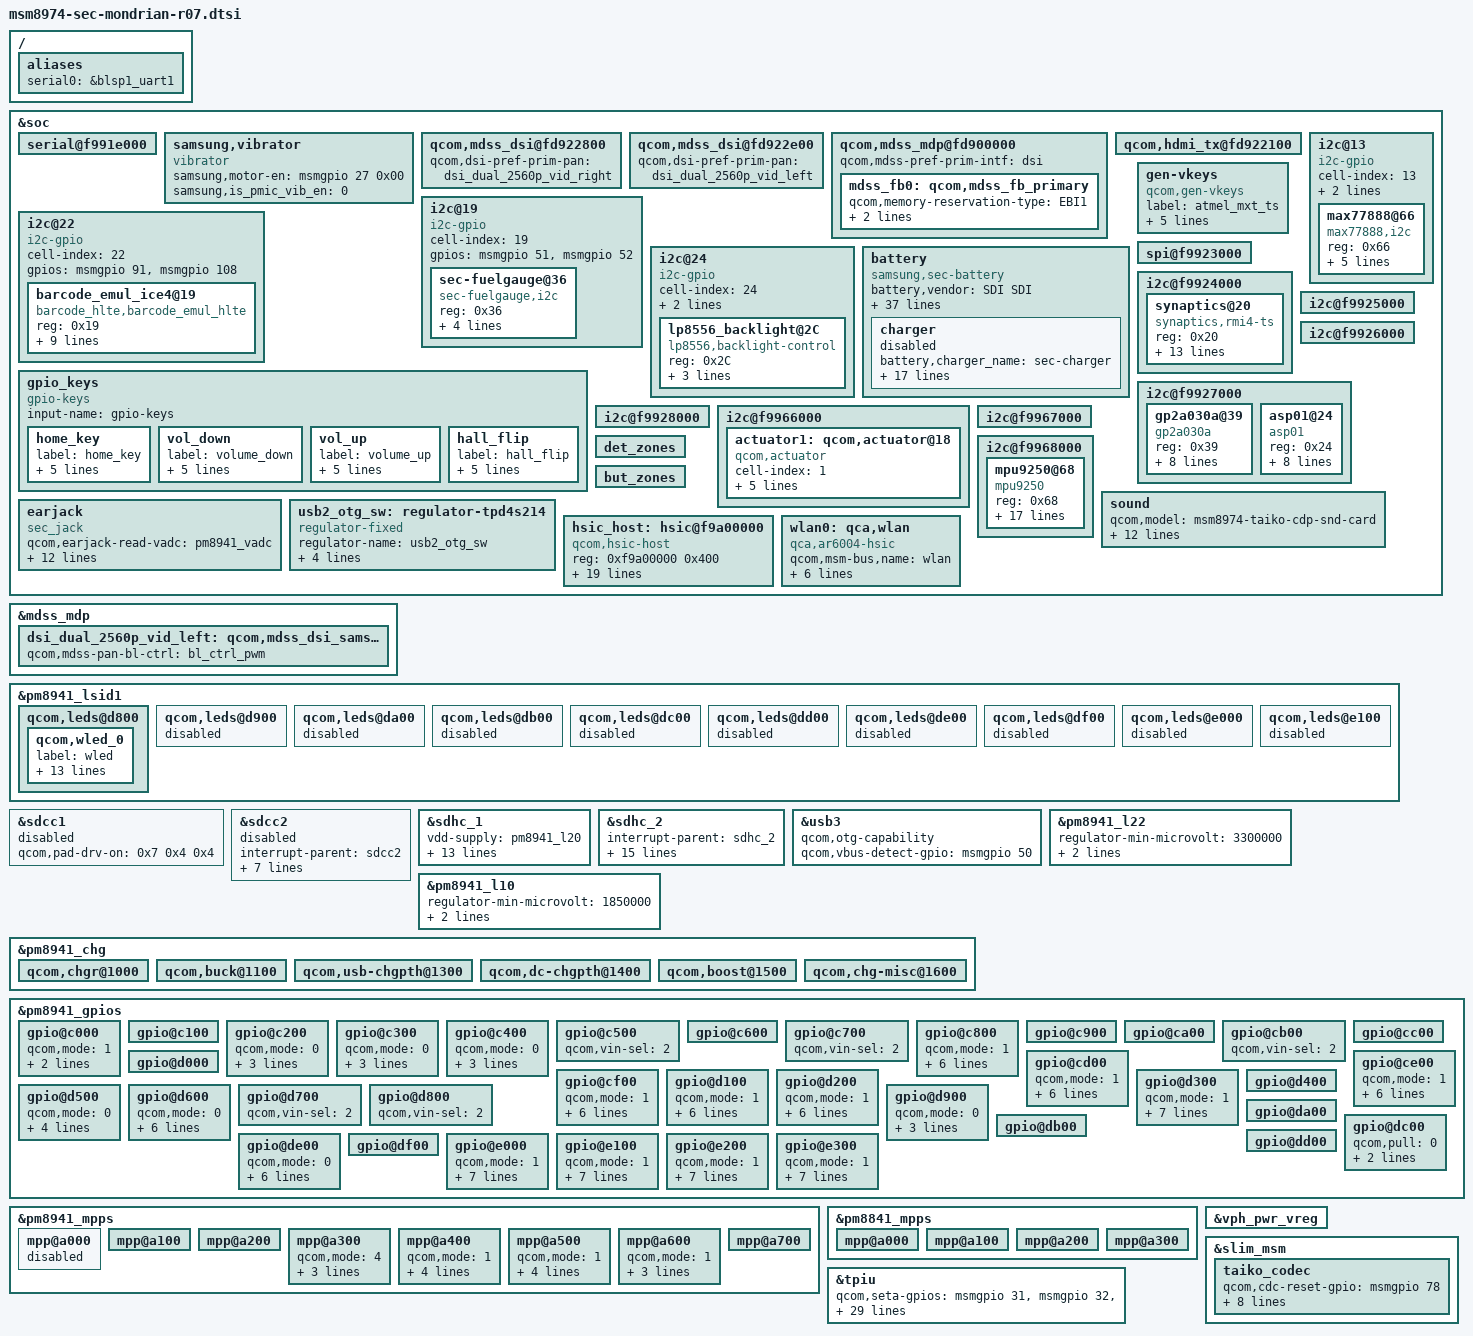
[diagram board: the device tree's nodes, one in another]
/* Copyright (c) 2012-2013, The Linux Foundation. All rights reserved.
 *
 * This program is free software; you can redistribute it and/or modify
 * it under the terms of the GNU General Public License version 2 and
 * only version 2 as published by the Free Software Foundation.
 *
 * This program is distributed in the hope that it will be useful,
 * but WITHOUT ANY WARRANTY; without even the implied warranty of
 * MERCHANTABILITY or FITNESS FOR A PARTICULAR PURPOSE.  See the
 * GNU General Public License for more details.
 */

/include/ "msm8974-leds.dtsi"
/include/ "msm8974-camera-sensor-skate.dtsi"
/include/ "msm8974-sii8240_mhl-mondrian-r00.dtsi"

/ {
	aliases {
		serial0 = &blsp1_uart1;
	};
};

&soc {
	serial@f991e000 {
		status = "ok";
	};

	samsung,vibrator{
                compatible = "vibrator";
                samsung,motor-en = <&msmgpio 27 0x00>;
		samsung,is_pmic_vib_en = <0>;
		status = "ok";
	};


	qcom,mdss_dsi@fd922800 {
		qcom,dsi-pref-prim-pan = <&dsi_dual_2560p_vid_right>;
	};

	qcom,mdss_dsi@fd922e00 {
		qcom,dsi-pref-prim-pan = <&dsi_dual_2560p_vid_left>;
	};

	qcom,mdss_mdp@fd900000 {
		qcom,mdss-pref-prim-intf = "dsi";
		mdss_fb0: qcom,mdss_fb_primary {
			qcom,memory-reservation-type = "EBI1";
			qcom,memblock-reserve = <0x03200000 0x01F00000>;
			qcom,mdss-fb-split = <800 800>;
		};
	};

	qcom,hdmi_tx@fd922100 {
		status = "ok";
	};

    i2c@13 {
        cell-index = <13>;
        compatible = "i2c-gpio";
        gpios = <&msmgpio 83 0 /* sda */
                 &msmgpio 84 0 /* scl */
                >;
		i2c-gpio,delay-us = <2>;
		#address-cells = <1>;
		#size-cells = <0>;
		max77888@66 {
		    compatible = "max77888,i2c";
		    reg = <0x66>;
		    interrupt-parent = <&pm8941_gpios>;
		    interrupts = <23 0>;
		    max77888,irq-gpio = <&pm8941_gpios 23 0x00>;
		    max77888,irq-base = <357>;
		    max77888,wakeup = <1>;
		};
    };

	i2c@19 {
        cell-index = <19>;
        compatible = "i2c-gpio";
        gpios = <&msmgpio 51 0 /* sda */
                 &msmgpio 52 0 /* scl */
                >;
		sec-fuelgauge@36 {
			compatible = "sec-fuelgauge,i2c";
			reg = <0x36>;
			fuelgauge,jig_gpio = <&msmgpio 76 0>;
			fuelgauge,fuel_int = <&pm8941_gpios 26 0x1>;
			fuelgauge,capacity_calculation_type = <7>;
			fuelgauge,fuel_alert_soc = <2>;
		};
	};

	i2c@22 {
		cell-index = <22>;
		compatible = "i2c-gpio";
		gpios = <&msmgpio 91 0 /* sda */
		&msmgpio 108 0 /* scl */
		>;

		barcode_emul_ice4@19 {
			compatible = "barcode_hlte,barcode_emul_hlte";
			reg = <0x19>;
			interrupt-parent = <&msmgpio>;
			interrupts = <64 0>;
			barcode,cresetb = <&msmgpio 57 0x01>;
			barcode,reset_n = <&msmgpio 132 0x00>;
			barcode,scl-gpio = <&msmgpio 108 0x00>;
			barcode,sda-gpio = <&msmgpio 91 0x00>;
			barcode,irq-gpio = <&msmgpio 64 0x00>;
			barcode,ir_led_en = <&pm8941_gpios 35 0x00>;
			barcode,i2c-pull-up = <1>;
		};
	};

	i2c@24 {
		cell-index = <24>;
		compatible = "i2c-gpio";
		gpios = <&msmgpio 10 0 /* sda */
				&msmgpio 11 0 /* scl */
		>;

		i2c-gpio,delay-us = <4>;

		lp8556_backlight@2C {
				compatible = "lp8556,backlight-control";
				reg = <0x2C>;
				lp8556,en-gpio = <&pm8941_gpios 19 0x00>;
				lp8556,scl-gpio = <&msmgpio 11 0x00>;
				lp8556,sda-gpio = <&msmgpio 10 0x00>;
		};
	};

	battery {
		status = "okay";
		compatible = "samsung,sec-battery";
		battery,vendor = "SDI SDI";
		battery,charger_name = "sec-charger";
		battery,fuelgauge_name = "sec-fuelgauge";
		battery,technology = <2>; /* POWER_SUPPLY_TECHNOLOGY_LION */
		battery,bat_irq_attr = <0x3>;

		battery,chip_vendor = "QCOM";
		battery,temp_adc_type = <1>; /* SEC_BATTERY_ADC_TYPE_AP */

		battery,polling_time = <10 30 30 30 3600>;

		battery,adc_check_count = <6>;

		battery,cable_check_type = <5>; /* SEC_BATTERY_CABLE_CHECK_NOUSBCHARGE | SEC_BATTERY_CABLE_CHECK_PSY */
		battery,cable_source_type = <1>; /* SEC_BATTERY_CABLE_SOURCE_EXTERNAL */
		battery,event_check;
		battery,event_waiting_time = <600>;
		battery,polling_type = <1>; /* SEC_BATTERY_MONITOR_ALARM */
		battery,monitor_initial_count = <3>;

		battery,battery_check_type = <4>; /* SEC_BATTERY_CHECK_FUELGAUGE */
		battery,check_count = <0>;
		battery,check_adc_max = <1440>;
		battery,check_adc_min = <0>;

		battery,ovp_uvlo_check_type = <3>; /* SEC_BATTERY_OVP_UVLO_CHGPOLLING */

		battery,thermal_source = <0>; /* SEC_BATTERY_THERMAL_SOURCE_FG */

		battery,temp_check_type = <2>; /* _BATTERY_TEMP_CHECK_TEMP */
		battery,temp_check_count = <1>;
		battery,full_check_type = <7>; /* SEC_BATTERY_FULLCHARGED_CHGPSY */
		battery,full_check_type_2nd = <3>; /* SEC_BATTERY_FULLCHARGED_TIME */
		battery,full_check_count = <1>;
		battery,chg_gpio_full_check = <0>;
		battery,chg_polarity_full_check = <1>;

		/* SEC_BATTERY_FULL_CONDITION_SOC |
		   SEC_BATTERY_FULL_CONDITION_NOTIMEFULL |
		   SEC_BATTERY_FULL_CONDITION_VCELL */
		battery,full_condition_type = <13>;
		battery,full_condition_soc = <97>;
		battery,full_condition_vcell = <4300>;

		battery,recharge_check_count = <1>;
		battery,recharge_condition_type = <4>; /* SEC_BATTERY_RECHARGE_CONDITION_VCELL */
		battery,recharge_condition_soc = <98>;
		battery,recharge_condition_vcell = <4300>;

		battery,charging_total_time = <36000>;
		battery,recharging_total_time = <5400>;
		battery,charging_reset_time = <0>;

		charger{
			status = "disable";
			/* Charger */
			battery,charger_name = "sec-charger";
			battery,chg_gpio_en = <0>;
			battery,chg_polarity_en = <0>;
			battery,chg_gpio_status = <0>;
			battery,chg_polarity_status = <0>;
			battery,chg_float_voltage = <4350>;
			battery,ovp_uvlo_check_type = <3>; /* SEC_BATTERY_OVP_UVLO_CHGPOLLING */
			battery,full_check_type = <7>; /* SEC_BATTERY_FULLCHARGED_CHGPSY */

			battery,input_current_limit = <1900 460 460 1900 460 900 1000 460 460 1000 650 1900 1900 460 1300 300 700 1300 300 1000 1900 460 460>;
			battery,fast_charging_current = <2100 0 460 2100 460 1200 1000 460 0 1200 750 2100 2100 0 1300 300 700 1300 300 1000 2100 0 0>;
			battery,full_check_current_1st = <350 0 350 350 350 350 350 350 0 350 350 350 350 0 350 350 350 350 350 350 350 0 0>;
			battery,full_check_current_2nd = <1200 0 1200 1200 1200 1200 1200 1200 0 1200 1200 1200 1200 0 1200 1200 1200 1200 1200 1200 1200 0 0>;
			battery,full_check_current_1st_sdi = <200 0 200 200 200 200 200 200 0 200 200 200 200 0 200 200 200 200 200 200 200 0 0>;
		};
	};

	qcom,hdmi_tx@fd922100 {
		status = "ok";
	};



	gen-vkeys {
		compatible = "qcom,gen-vkeys";
		label = "atmel_mxt_ts";
		qcom,disp-maxx = <720>;
		qcom,disp-maxy = <1280>;
		qcom,panel-maxx = <760>;
		qcom,panel-maxy = <1424>;
		qcom,key-codes = <158 139 102 217>;
	};

	gpio_keys {
		compatible = "gpio-keys";
		input-name = "gpio-keys";

		home_key {
			label = "home_key";
			gpios = <&pm8941_gpios 3 0x1>;
			linux,input-type = <1>;
			linux,code = <172>;
			gpio-key,wakeup;
			debounce-interval = <15>;
		};

		vol_down {
			label = "volume_down";
			gpios = <&pm8941_gpios 2 0x1>;
			linux,input-type = <1>;
			linux,code = <114>;
			gpio-key,wakeup;
			debounce-interval = <15>;
		};

		vol_up {
			label = "volume_up";
			gpios = <&pm8941_gpios 5 0x1>;
			linux,input-type = <1>;
			linux,code = <115>;
			gpio-key,wakeup;
			debounce-interval = <15>;
		};

		hall_flip {
			label = "hall_flip";
			gpios = <&pm8941_gpios 31 0>;
			linux,input-type = <1>;
			linux,code = <0x15>;
			gpio-key,wakeup;
			debounce-interval = <15>;
		};
	};

	/* BLSP#1 */
	spi@f9923000 {
		status = "okay";
	};

	/* BLSP#2 */
	i2c@f9924000 {
		status = "okay";
		synaptics@20 {
			compatible = "synaptics,rmi4-ts";
			reg = <0x20>;
			interrupt-parent = <&pm8941_gpios>;
			interrupts = <30 0>;
			avdd-supply = <&pm8941_l22>;
			vcc_i2c-supply = <&pm8941_l10>;
			synaptics,supply-num = <2>;			/* the number of regulators */
			synaptics,supply-name = "8941_l22", "8941_l10";	/* the name of regulators, in power-on order */
			synaptics,irq-gpio = <&pm8941_gpios 30 0x1>;
			synaptics,reset-gpio = <&msmgpio 41 0x1>;
			synaptics,id-gpio = <&msmgpio 42 0x0>;
			synaptics,i2c-pull-up = <1>;
			synaptics,tsp-project = "Mondrian";
			synaptics,tsp-coords = <1599 2559>;
			synaptics,tsp-keycodes	= <254 158>;

			/* Set regulators' voltage below. Search with "8941_l22", "8941_l10" */
		};
	};

	/* BLSP#3 */
	i2c@f9925000 {
	};

	/* BLSP#4 */
	i2c@f9926000 {
	};

	/* BLSP#5 */
	i2c@f9927000 {
		status = "okay";
		gp2a030a@39 {
			compatible = "gp2a030a";
			reg = <0x39>;
			gp2a030a,vled_gpio = <&msmgpio 54 0x0>;
			gp2a030a,irq_gpio = <&msmgpio 74 0x0>;
			gp2a030a-vcc-supply = <&pm8941_l18>;
			gp2a030a-lvs1-supply = <&pm8941_lvs1>;
			gp2a030a,con_gpio = <&pm8941_mpps 5 0x0>;
			qcom,gp2a030a-vcc-voltage-level = <2850000 2850000>;
			qcom,gp2a030a-vcc-always-on;
		};
		asp01@24 {
			compatible = "asp01";
			reg = <0x24>;
			asp01,irq_gpio = <&msmgpio 79 0x0>;
			asp01-vcc-supply = <&pm8941_l18>;
			asp01-lvs1-supply = <&pm8941_lvs1>;
			asp01,cr_cs_div = <10 12 10 12>;
			asp01,init_code = <0x5a 0x33 0x40 0x40 0x3c
							   0x30 0x30 0x33 0x34 0x21
							   0x04 0x40 0x00 0x10 0x30
							   0x28 0x50 0x78 0x27 0x20
							   0x27 0x83 0x3f 0x48 0x20
							   0x04 0x27 0x00>;
			qcom,asp01-vcc-voltage-level = <2850000 2850000>;
			qcom,asp01-vcc-always-on;
		};
	};

	/* BLSP#6 */
	i2c@f9928000 {
		status = "okay";
	};

	/* BLSP#7 */
	/* i2c@f9963000 {
	}; */

	/* BLSP#8 */
	/* i2c@f9964000 {
	}; */

	/* BLSP#10 */
	i2c@f9966000 {
		actuator1: qcom,actuator@18 {
			compatible = "qcom,actuator";
			cell-index = <1>;
			reg = <0x18>;
			gpios = <&msmgpio 55 0>,
					<&msmgpio 56 0>;
			qcom,gpio-req-tbl-num = <0 1>;
			qcom,gpio-req-tbl-flags = <1 1>;
			qcom,gpio-req-tbl-label = "I2C_DATA0",
							  		"I2C_CLK0";
		};
	};

	/* BLSP#11 */
	i2c@f9967000 {
	};

	/* BLSP#12 */
	i2c@f9968000 {
		status = "okay";
		mpu9250@68 {
			compatible = "mpu9250";
			reg = <0x68>;
			mpu9250,device_rev = <7>;
			mpu9250,irq_gpio = <&msmgpio 86 0x0>;
			mpu9250,int_config = <0>;
			mpu9250,level_shifter = <0>;
			mpu9250,sec_slave_type = <2>;
			mpu9250,sec_slave_id = <18>;
			mpu9250,secondary_i2c_addr = <0x0C>;
			mpu9250,orientation = <1 2 1 2 1 1 1 1 0>;
			mpu9250,secondary_orientation = <2 1 1 1 2 1 1 1 2>;
			mpu9250,key = <211 22 205 7
						   217 186 151 55
			               206 254 35 144
			               225 102 47 50>;
			mpu9250-vcc-supply = <&pm8941_l18>;
			mpu9250-lvs1-supply = <&pm8941_lvs1>;
			qcom,mpu9250-vcc-voltage-level = <2850000 2850000>;
			qcom,mpu9250-vcc-always-on;
		};
	};

	sound {
		qcom,model = "msm8974-taiko-cdp-snd-card";
		qcom,hdmi-audio-rx;
		qcom,mainmic-bias-gpio = <&pm8941_gpios 33 0>;
		qcom,spkamp-en-gpio = <&msmgpio 82 0>;

		qcom,audio-routing =
			"RX_BIAS", "MCLK",
			"LDO_H", "MCLK",
			"AIF4 MAD", "MCLK",
			"Lineout_1 amp", "LINEOUT1",
			"Lineout_2 amp", "LINEOUT2",
			"Lineout_3 amp", "LINEOUT3",
			"Lineout_4 amp", "LINEOUT4",
			"AMIC1", "Main Mic Bias",
			"Main Mic Bias", "Main Mic",
			"AMIC2", "MIC BIAS2 External",
			"MIC BIAS2 External", "Headset Mic",
			"AMIC4", "MIC BIAS3 External",
			"MIC BIAS3 External", "Sub Mic";
	};

	det_zones: det_zones {
		#list-det-cells = <4>;
	};

	but_zones: but_zones {
		#list-but-cells = <3>;
	};

	earjack {
		compatible = "sec_jack";
		qcom,earjack-read-vadc = <&pm8941_vadc>;
		qcom,earjack-detect-gpio = <&pm8941_gpios 22 0>;
		qcom,earjack-micbias-gpio = <&pm8941_gpios 34 0>;
		qcom,earjack-sendend-gpio = <&msmgpio 77 0>;
		qcom,earjack-fsa_en-gpio = <&msmgpio 8 1>;
		qcom,send-end-active-high;

		det-zones-list = <&det_zones 0 10000 10 0>,
						 <&det_zones 900 10000 10 0>,
						 <&det_zones 2400 10000 10 1>,
						 <&det_zones 9999 10000 10 1>;
		but-zones-list = <&but_zones 0 0 155>,
						 <&but_zones 1 156 310>,
						 <&but_zones 2 311 800>;
		mpp-channel-scaling = <4 1 3>;
	};

	usb2_otg_sw: regulator-tpd4s214 {
		compatible = "regulator-fixed";
		regulator-name = "usb2_otg_sw";
		gpio = <&pm8941_gpios 18 0>;
		parent-supply = <&pm8941_boost>;
		startup-delay-us = <17000>;
		enable-active-high;
	};

	hsic_host: hsic@f9a00000 {
		compatible = "qcom,hsic-host";
		reg = <0xf9a00000 0x400>;
		#address-cells = <0>;
		interrupt-parent = <&hsic_host>;
		interrupts = <0 1 2>;
		#interrupt-cells = <1>;
		interrupt-map-mask = <0xffffffff>;
		interrupt-map = <0 &intc 0 136 0
			1 &intc 0 148 0
			2 &msmgpio 144 0x8>;
		interrupt-names = "core_irq", "async_irq", "wakeup";
		HSIC_VDDCX-supply = <&pm8841_s2>;
		HSIC_GDSC-supply = <&gdsc_usb_hsic>;
		hsic,strobe-gpio = <&msmgpio 144 0x00>;
		hsic,data-gpio = <&msmgpio 145 0x00>;
		hsic,resume-gpio = <&msmgpio 80 0x00>;
		hsic,ignore-cal-pad-config;
		hsic,strobe-pad-offset = <0x2050>;
		hsic,data-pad-offset = <0x2054>;
		qcom,phy-susp-sof-workaround;

		qcom,msm-bus,name = "hsic";
		qcom,msm-bus,num-cases = <2>;
		qcom,msm-bus,num-paths = <1>;
		qcom,msm-bus,vectors-KBps =
				<85 512 0 0>,
				<85 512 40000 160000>;
        };

	wlan0: qca,wlan {
		compatible = "qca,ar6004-hsic";
		qcom,msm-bus,name = "wlan";
		qcom,msm-bus,num-cases = <5>;
		qcom,msm-bus,active-only = <0>;
		qcom,msm-bus,num-paths = <1>;
		qcom,msm-bus,vectors-KBps =
				<85 512 0 0>,
				<85 512 40000 160000>,
				<85 512 40000 320000>,
				<85 512 40000 480000>,
				<85 512 40000 800000>;
	};
};

&mdss_mdp {
	dsi_dual_2560p_vid_left: qcom,mdss_dsi_samsung_dual_2560p_video_left {
		qcom,mdss-pan-bl-ctrl = "bl_ctrl_pwm";
	};
};

&pm8941_lsid1 {
	qcom,leds@d800 {
		status = "okay";
		qcom,wled_0 {
			label = "wled";
			linux,name = "wled:backlight";
			linux,default-trigger = "bkl-trigger";
			qcom,cs-out-en;
			qcom,op-fdbck = <1>;
			qcom,default-state = "off";
			qcom,max-current = <25>;
			qcom,ctrl-delay-us = <0>;
			qcom,boost-curr-lim = <5>;
			qcom,cp-sel = <0>;
			qcom,switch-freq = <11>;
			qcom,ovp-val = <2>;
			qcom,num-strings = <3>;
			qcom,id = <0>;
		};
	};

	qcom,leds@d900 {
		status = "disabled";
	};

	qcom,leds@da00 {
		status = "disabled";
	};

	qcom,leds@db00 {
		status = "disabled";
	};

	qcom,leds@dc00 {
		status = "disabled";
	};

	qcom,leds@dd00 {
		status = "disabled";
	};

	qcom,leds@de00 {
		status = "disabled";
	};

	qcom,leds@df00 {
		status = "disabled";
	};

	qcom,leds@e000 {
		status = "disabled";
	};

	qcom,leds@e100 {
		status = "disabled";
	};
};

&sdcc1 {
       status = "disabled";
};

&sdcc2 {
	#address-cells = <0>;
	interrupt-parent = <&sdcc2>;
	interrupts = <0 1 2>;
	#interrupt-cells = <1>;
	interrupt-map-mask = <0xffffffff>;
	interrupt-map = <0 &intc 0 125 0
			1 &intc 0 220 0
			2 &msmgpio 62 0x3>;
	interrupt-names = "core_irq", "bam_irq", "status_irq";
	cd-gpios = <&msmgpio 62 0x1>;
	wp-gpios = <&pm8941_gpios 29 0x1>;
	status = "disabled";
};

&sdhc_1 {
	vdd-supply = <&pm8941_l20>;
	vdd-io-supply = <&pm8941_s3>;

	qcom,vdd-always-on;
	qcom,vdd-lpm-sup;
	qcom,vdd-voltage-level = <2950000 2950000>;
	qcom,vdd-current-level = <800 500000>;

	qcom,vdd-io-always-on;
	qcom,vdd-io-voltage-level = <1800000 1800000>;
	qcom,vdd-io-current-level = <250 154000>;

	qcom,pad-pull-on = <0x0 0x3 0x3>; /* no-pull, pull-up, pull-up */
	qcom,pad-pull-off = <0x0 0x3 0x3>; /* no-pull, pull-up, pull-up */
	qcom,pad-drv-on = <0x4 0x4 0x4>; /* 10mA, 10mA, 10mA */
	qcom,pad-drv-off = <0x0 0x0 0x0>; /* 2mA, 2mA, 2mA */

	qcom,nonremovable;
	status = "ok";
};

&sdhc_2 {
	#address-cells = <0>;
	interrupt-parent = <&sdhc_2>;
	interrupts = <0 1 2>;
	#interrupt-cells = <1>;
	interrupt-map-mask = <0xffffffff>;
	interrupt-map = <0 &intc 0 125 0
			1 &intc 0 221 0
			2 &msmgpio 62 0x3>;
	interrupt-names = "hc_irq", "pwr_irq", "status_irq";
	cd-gpios = <&msmgpio 62 0x1>;

	vdd-supply = <&pm8941_l21>;
	vdd-io-supply = <&pm8941_l13>;

	qcom,vdd-voltage-level = <2950000 2950000>;
	qcom,vdd-current-level = <9000 800000>;

	qcom,vdd-io-voltage-level = <1800000 2950000>;
	qcom,vdd-io-current-level = <6 22000>;

	qcom,pad-pull-on = <0x0 0x3 0x3>; /* no-pull, pull-up, pull-up */
	qcom,pad-pull-off = <0x0 0x3 0x3>; /* no-pull, pull-up, pull-up */
	qcom,pad-drv-on = <0x4 0x4 0x4>; /* 10mA, 10mA, 10mA */
	qcom,pad-drv-off = <0x0 0x0 0x0>; /* 2mA, 2mA, 2mA */
	status = "ok";
};

/* Drive strength recommendations for clock line from hardware team is 10 mA.
 * But since the driver has been been using the below values from the start
 * without any problems, continue to use those.
 */
&sdcc1 {
	qcom,pad-drv-on = <0x7 0x4 0x4>; /* 16mA, 10mA, 10mA */
};

&sdcc2 {
	qcom,pad-drv-on = <0x7 0x4 0x4>; /* 16mA, 10mA, 10mA */
};

&sdhc_1 {
	qcom,pad-drv-on = <0x7 0x4 0x4>; /* 16mA, 10mA, 10mA */
};

&sdhc_2 {
	qcom,pad-drv-on = <0x7 0x4 0x4>; /* 16mA, 10mA, 10mA */
};

&usb3 {
	qcom,otg-capability;
	qcom,vbus-detect-gpio = <&msmgpio 50 0>;
};

&pm8941_l22 {
/* TSP 3.3V regulator */
	regulator-min-microvolt = <3300000>;
	regulator-max-microvolt = <3300000>;
	qcom,init-voltage = <3300000>;
};

&pm8941_l10 {
/* TSP 1.8V IO regulator */
	regulator-min-microvolt = <1850000>;
	regulator-max-microvolt = <1850000>;
	qcom,init-voltage = <1850000>;
};

&pm8941_chg {
	status = "ok";

	qcom,chgr@1000 {
		status = "ok";
	};

	qcom,buck@1100 {
		status = "ok";
	};

	qcom,usb-chgpth@1300 {
		status = "ok";
	};

	qcom,dc-chgpth@1400 {
		status = "ok";
	};

	qcom,boost@1500 {
		status = "ok";
	};

	qcom,chg-misc@1600 {
		status = "ok";
	};
};

&pm8941_gpios {
	gpio@c000 { /* GPIO 1 */
		/* CAM_MOVIE_EN pin */
		qcom,mode = <1>;	/* DIG_OUT */
		qcom,pull = <4>;	/* QPNP_PIN_PULL_DOWN */
		qcom,vin-sel = <2>;		/* PM8941 S3 = 1.8 V */
	};

	gpio@c100 { /* GPIO 2 */
	};

	gpio@c200 { /* GPIO 3 */
		qcom,mode = <0>;
		qcom,pull = <0>;
		qcom,vin-sel = <2>;
		qcom,src-sel = <0>;
	};

	gpio@c300 { /* GPIO 4 */
		qcom,mode = <0>;
		qcom,pull = <0>;
		qcom,vin-sel = <2>;
		qcom,src-sel = <0>;
	};

	gpio@c400 { /* GPIO 5 */
		qcom,mode = <0>;
		qcom,pull = <0>;
		qcom,vin-sel = <2>;
		qcom,src-sel = <0>;
	};

	gpio@c500 { /* GPIO 6 */
		/* VT_CAM_STBY */
		qcom,vin-sel = <2>;		/* QPNP_PIN_VIN2 */
	};

	gpio@c600 { /* GPIO 7 */
	};

	gpio@c700 { /* GPIO 8 */
		/* 2M_A2.8V_EN */
		qcom,vin-sel = <2>;		/* PM8941 S3 = 1.8 V */
	};

	gpio@c800 { /* GPIO 9 */
		qcom,mode = <1>;  /* QPNP_PIN_MODE_DIG_OUT */
		qcom,output-type = <0>; /* QPNP_PIN_OUT_BUF_CMOS */
		qcom,pull = <5>; /* QPNP_PIN_PULL_NO */
		qcom,vin-sel = <2>; /* QPNP_PIN_VIN2 */
		qcom,out-strength = <3>; /* QPNP_PIN_OUT_STRENGTH_HIGH */
		qcom,src-sel = <0>; /* QPNP_PIN_SEL_FUNC_CONSTANT */
		qcom,master-en = <1>;
	};

	gpio@c900 { /* GPIO 10 */
	};

	gpio@ca00 { /* GPIO 11 */
	};

	gpio@cb00 { /* GPIO 12 */
		/* 8M_AVDD_LDO_EN */
		qcom,vin-sel = <2>;		/* PM8941 S3 = 1.8 V */
	};

	gpio@cc00 { /* GPIO 13 */
	};

	gpio@cd00 { /* GPIO 14 */
		qcom,mode = <1>;  /* QPNP_PIN_MODE_DIG_OUT */
		qcom,output-type = <0>; /* QPNP_PIN_OUT_BUF_CMOS */
		qcom,pull = <5>; /* QPNP_PIN_PULL_NO */
		qcom,vin-sel = <2>; /* QPNP_PIN_VIN2 */
		qcom,out-strength = <3>; /* QPNP_PIN_OUT_STRENGTH_HIGH */
		qcom,src-sel = <0>; /* QPNP_PIN_SEL_FUNC_CONSTANT */
		qcom,master-en = <1>;
	};

	gpio@ce00 { /* GPIO 15 */
		qcom,mode = <1>;
		qcom,output-type = <0>;
		qcom,pull = <5>;
		qcom,vin-sel = <2>;
		qcom,out-strength = <1>;
		qcom,src-sel = <2>;
		qcom,master-en = <1>;
	};

	gpio@cf00 { /* GPIO 16 */
		qcom,mode = <1>;
		qcom,output-type = <0>;
		qcom,pull = <2>;
		qcom,vin-sel = <2>;
		qcom,out-strength = <2>;
		qcom,src-sel = <2>;
		qcom,master-en = <1>;
	};

	gpio@d000 { /* GPIO 17 */
	};

	gpio@d100 { /* GPIO 18 */
		/* usb2_otg_sw regulator enable */
		qcom,mode = <1>;		/* Digital output */
		qcom,output-type = <0>;		/* CMOS logic */
		qcom,invert = <0>; 		/* Output low initially */
		qcom,vin-sel = <2>; 		/* PM8941 S3 = 1.8 V */
		qcom,src-sel = <0>; 		/* Constant */
		qcom,out-strength = <2>;	/* Medium drive strength */
		qcom,master-en = <1>;		/* Enable GPIO */
	};

	gpio@d200 { /* GPIO 19 */
		qcom,mode = <1>;		/* QPNP_PIN_MODE_DIG_OUT */
		qcom,output-type = <0>;		/* QPNP_PIN_OUT_BUF_CMOS */
		qcom,pull = <5>;		/* QPNP_PIN_PULL_NO */
		qcom,vin-sel = <2>;		/* QPNP_PIN_VIN2 */
		qcom,out-strength = <2>;	/* QPNP_PIN_OUT_STRENGTH_MED */
		qcom,src-sel = <0>;		/* QPNP_PIN_SEL_FUNC_CONSTANT */
		qcom,master-en = <1>;
	};

	gpio@d300 { /* GPIO 20 */
		qcom,mode = <1>;		/* QPNP_PIN_MODE_DIG_OUT */
		qcom,output-type = <0>;		/* QPNP_PIN_OUT_BUF_CMOS */
		qcom,invert = <0>; 		/* Output low initially */
		qcom,pull = <5>;		/* QPNP_PIN_PULL_NO */
		qcom,vin-sel = <2>;		/* QPNP_PIN_VIN2 */
		qcom,out-strength = <2>;	/* QPNP_PIN_OUT_STRENGTH_MED */
		qcom,src-sel = <0>;		/* QPNP_PIN_SEL_FUNC_CONSTANT */
		qcom,master-en = <1>;
	};

	gpio@d400 { /* GPIO 21 */
	};

	gpio@d500 { /* GPIO 22 */
		qcom,mode = <0>;	/* input */
		qcom,pull = <5>;		/* pull-up with 30uA current strength */
		qcom,vin-sel = <2>;	/* VIN=S3 */
		qcom,src-sel = <0>;	/* constant */
		qcom,master_en = <1>;
	};

	gpio@d600 { /* GPIO 23 */
		qcom,mode = <0>;		/* QPNP_PIN_MODE_DIG_IN */
		qcom,output-type = <0>;		/* QPNP_PIN_OUT_BUF_CMOS */
		qcom,pull = <5>;		/* QPNP_PIN_PULL_NO */
		qcom,vin-sel = <2>; 		/* QPNP_PIN_VIN2 */
		qcom,out-strength = <3>;	/* QPNP_PIN_OUT_STRENGTH_HIGH */
		qcom,src-sel = <0>;		/* QPNP_PIN_SEL_FUNC_CONSTANT*/
		qcom,master-en = <1>;
	};

	gpio@d700 { /* GPIO 24 */
		/* VT sensor rst pin */
		qcom,vin-sel = <2>;		/* PM8941 S3 = 1.8 V */
	};

	gpio@d800 { /* GPIO 25 */
		/* 8M sensor rst pin */
		qcom,vin-sel = <2>;		/* PM8941 S3 = 1.8 V */
	};

	gpio@d900 { /* GPIO 26 */
		qcom,mode = <0>;		/* QPNP_PIN_MODE_DIG_IN */
		qcom,pull = <5>;		/* QPNP_PIN_PULL_NO */
		qcom,vin-sel = <2>;		/* QPNP_PIN_VIN2 */
		qcom,src-sel = <0>;		/* QPNP_PIN_SEL_FUNC_CONSTANT */
	};

	gpio@da00 { /* GPIO 27 */
	};

	gpio@db00 { /* GPIO 28 */
	};

	gpio@dc00 { /* GPIO 29 */
		qcom,pull = <0>; /* set to default pull */
		qcom,master-en = <1>;
		qcom,vin-sel = <2>; /* select 1.8 V source */
	};

	gpio@dd00 { /* GPIO 30 */
	};

	gpio@de00 { /* GPIO 31 */
		qcom,mode = <0>;
		qcom,output-type = <0>;
		qcom,vin-sel = <2>;
		qcom,out-strength = <2>;
		qcom,src-sel = <3>;
		qcom,pull = <5>;
		qcom,master-en = <1>;
	};

	gpio@df00 { /* GPIO 32 */
	};

	gpio@e000 { /* GPIO 33 */
		qcom,mode = <1>;		/* Digital output */
		qcom,output-type = <0>;	/* CMOS logic */
		qcom,pull = <5>;			/* QPNP_PIN_PULL_NO */
		qcom,invert = <0>;		/* Output low initially */
		qcom,vin-sel = <2>;		/* PM8941 S3 = 1.8 V */
		qcom,src-sel = <0>;		/* Constant */
		qcom,out-strength = <2>;	/* Medium drive strength */
		qcom,master-en = <1>;	/* Enable GPIO */
	};

	gpio@e100 { /* GPIO 34 */
		qcom,mode = <1>;		/* Digital output */
		qcom,output-type = <0>;	/* CMOS logic */
		qcom,pull = <5>;			/* QPNP_PIN_PULL_NO */
		qcom,invert = <0>;		/* Output low initially */
		qcom,vin-sel = <2>;		/* PM8941 S3 = 1.8 V */
		qcom,src-sel = <0>;		/* Constant */
		qcom,out-strength = <2>;	/* Medium drive strength */
		qcom,master-en = <1>;	/* Enable GPIO */
	};

	gpio@e200 { /* GPIO 35 */
		qcom,mode = <1>;		/* Digital output */
		qcom,output-type = <0>;	/* CMOS logic */
		qcom,pull = <5>;			/* QPNP_PIN_PULL_NO */
		qcom,invert = <0>;		/* Output low initially */
		qcom,vin-sel = <2>;		/* PM8941 S3 = 1.8 V */
		qcom,src-sel = <0>;		/* Constant */
		qcom,out-strength = <2>;	/* Medium drive strength */
		qcom,master-en = <1>;	/* Enable GPIO */
	};

	gpio@e300 { /* GPIO 36 */
		qcom,mode = <1>;  /* QPNP_PIN_MODE_DIG_OUT */
		qcom,output-type = <0>; /* QPNP_PIN_OUT_BUF_CMOS */
		qcom,invert = <0>;	/* QPNP_PIN_INVERT_DISABLE */
		qcom,pull = <5>; /* QPNP_PIN_PULL_NO */
		qcom,vin-sel = <2>; /* QPNP_PIN_VIN2 */
		qcom,out-strength = <3>; /* QPNP_PIN_OUT_STRENGTH_HIGH */
		qcom,src-sel = <3>; /* QPNP_PIN_SEL_FUNC_2 */
		qcom,master-en = <1>;
	};
};

&pm8941_mpps {

	mpp@a000 { /* MPP 1 */
		status = "disabled";
	};

	mpp@a100 { /* MPP 2 */
	};

	mpp@a200 { /* MPP 3 */
	};

	mpp@a300 { /* MPP 4 */
		qcom,mode = <4>; /* AIN input */
		qcom,ain-route = <3>; /* AMUX 8 */
		qcom,master-en = <1>;/* Enable MPP4 */
		qcom,src-sel = <0>; /* Function constant */
	};

	mpp@a400 { /* MPP 5 */
		/* SPI_ETH config */
		qcom,mode = <1>; /* DIG_OUT */
		qcom,output-type = <0>; /* CMOS */
		qcom,vin-sel = <2>; /* PM8941_S3 1.8V > 1.6V */
		qcom,src-sel = <0>; /* CONSTANT */
		qcom,master-en = <1>; /* ENABLE MPP */
	};

	mpp@a500 { /* MPP 6 */
		/* SPI_ETH_RST config */
		qcom,mode = <1>; /* DIG_OUT */
		qcom,output-type = <0>; /* CMOS */
		qcom,vin-sel = <2>; /* PM8941_S3 1.8V > 1.6V */
		qcom,src-sel = <0>; /* CONSTANT */
		qcom,master-en = <1>; /* ENABLE MPP */
	};

	mpp@a600 { /* MPP 7 */
		/* CAM_FLASH_EN pin */
		qcom,mode = <1>;		/* DIG_OUT */
		qcom,vin-sel = <2>;		/* S3A 1.8v */
		qcom,src-sel = <0>;		/* CONSTANT */
		qcom,master-en = <1>;	/* ENABLE MPP */
	};

	mpp@a700 { /* MPP 8 */
	};
};

&pm8841_mpps {

	mpp@a000 { /* MPP 1 */
	};

	mpp@a100 { /* MPP 2 */
	};

	mpp@a200 { /* MPP 3 */
	};

	mpp@a300 { /* MPP 4 */
	};
};

/* CoreSight */
&tpiu {
	qcom,seta-gpios = <&msmgpio 31 0>,
			  <&msmgpio 32 0>,
			  <&msmgpio 33 0>,
			  <&msmgpio 34 0>,
			  <&msmgpio 35 0>,
			  <&msmgpio 36 0>,
			  <&msmgpio 37 0>,
			  <&msmgpio 38 0>,
			  <&msmgpio 39 0>,
			  <&msmgpio 40 0>,
			  <&msmgpio 41 0>,
			  <&msmgpio 42 0>,
			  <&msmgpio 43 0>,
			  <&msmgpio 44 0>,
			  <&msmgpio 45 0>,
			  <&msmgpio 46 0>,
			  <&msmgpio 47 0>,
			  <&msmgpio 48 0>;
	qcom,seta-gpios-func = <4 4 4 3 4 4 4 3 4 3 5 5 5 5 4 4 5 5>;
	qcom,seta-gpios-drv =  <7 7 7 7 7 7 7 7 7 7 7 7 7 7 7 7 7 7>;
	qcom,seta-gpios-pull = <0 0 0 0 0 0 0 0 0 0 0 0 0 0 0 0 0 0>;
	qcom,seta-gpios-dir =  <2 2 2 2 2 2 2 2 2 2 2 2 2 2 2 2 2 2>;

	qcom,setb-gpios = <&msmgpio 15 0>,
			  <&msmgpio 16 0>,
			  <&msmgpio 17 0>,
			  <&msmgpio 18 0>,
			  <&msmgpio 19 0>,
			  <&msmgpio 20 0>,
			  <&msmgpio 21 0>,
			  <&msmgpio 22 0>,
			  <&msmgpio 23 0>,
			  <&msmgpio 24 0>,
			  <&msmgpio 25 0>,
			  <&msmgpio 26 0>,
			  <&msmgpio 27 0>,
			  <&msmgpio 28 0>,
			  <&msmgpio 89 0>,
			  <&msmgpio 90 0>,
			  <&msmgpio 91 0>,
			  <&msmgpio 92 0>;
	qcom,setb-gpios-func = <2 2 2 2 5 5 5 5 6 6 6 7 7 5 2 3 3 3>;
	qcom,setb-gpios-drv =  <7 7 7 7 7 7 7 7 7 7 7 7 7 7 7 7 7 7>;
	qcom,setb-gpios-pull = <0 0 0 0 0 0 0 0 0 0 0 0 0 0 0 0 0 0>;
	qcom,setb-gpios-dir =  <2 2 2 2 2 2 2 2 2 2 2 2 2 2 2 2 2 2>;
};

&vph_pwr_vreg {
	status = "ok";
};

&slim_msm {
	taiko_codec {
		qcom,cdc-reset-gpio = <&msmgpio 78 0>;
		qcom,cdc-micbias1-ext-cap;
		qcom,cdc-micbias2-ext-cap;
		qcom,cdc-micbias3-ext-cap;
		qcom,cdc-micbias4-ext-cap;

		/*
		 * Liquid has external spkrdrv supply. Give a dummy supply to
		 * make codec driver's happy.
		 */
		cdc-vdd-spkdrv-supply = <&vph_pwr_vreg>;
		qcom,cdc-vdd-spkdrv-voltage = <0 0>;
		qcom,cdc-vdd-spkdrv-current = <0>;

		qcom,cdc-on-demand-supplies = "cdc-vdd-spkdrv";
	};
};

